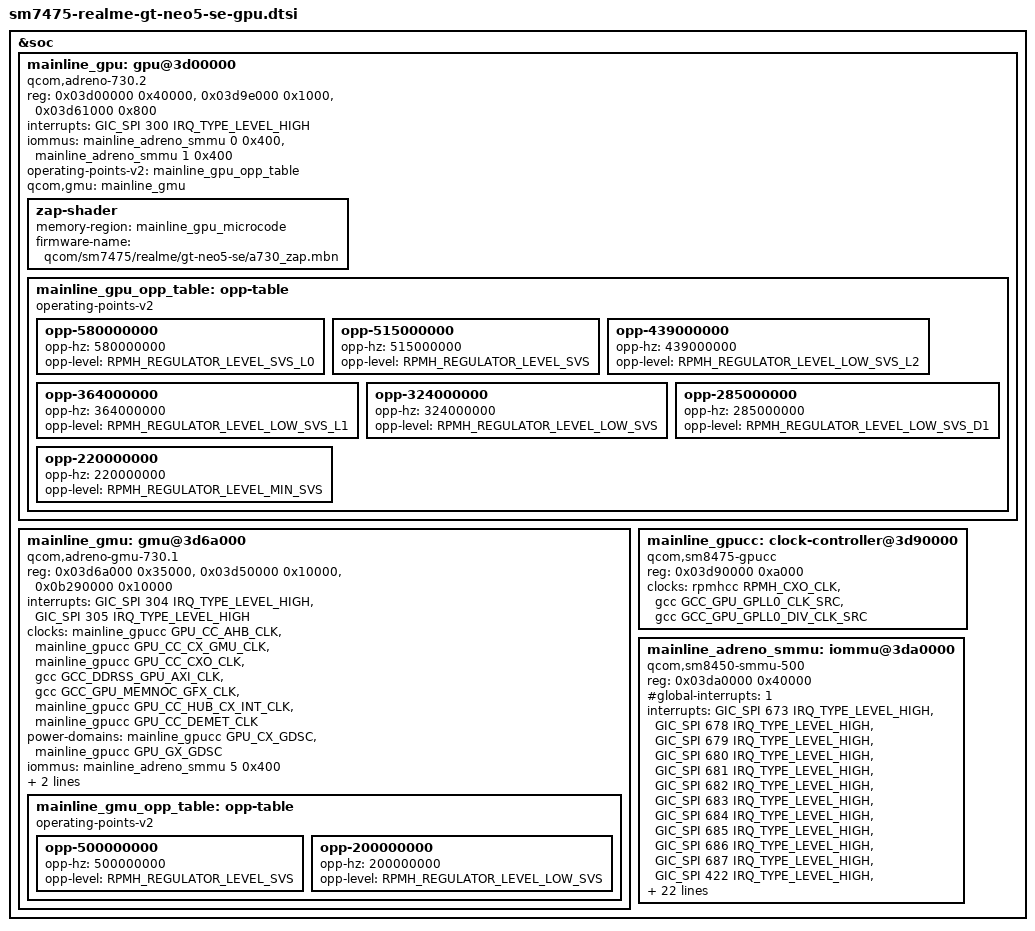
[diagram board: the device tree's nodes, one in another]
// SPDX-License-Identifier: (GPL-2.0-only OR BSD-3-Clause)
/* Cape GPU: stock chip ID 0x07030002, 2 MiB GMEM, 220..580 MHz. */
#include <dt-bindings/clock/qcom,sm8450-gpucc.h>

&soc {
	mainline_gpu: gpu@3d00000 {
		compatible = "qcom,adreno-730.2", "qcom,adreno";
		reg = <0x03d00000 0x40000>,
		      <0x03d9e000 0x1000>,
		      <0x03d61000 0x800>;
		reg-names = "kgsl_3d0_reg_memory",
			    "cx_mem",
			    "cx_dbgc";

		interrupts = <GIC_SPI 300 IRQ_TYPE_LEVEL_HIGH>;

		iommus = <&mainline_adreno_smmu 0 0x400>,
			 <&mainline_adreno_smmu 1 0x400>;

		operating-points-v2 = <&mainline_gpu_opp_table>;

		qcom,gmu = <&mainline_gmu>;
		#cooling-cells = <2>;

		status = "okay";

		zap-shader {
			memory-region = <&mainline_gpu_microcode>;
			firmware-name = "qcom/sm7475/realme/gt-neo5-se/a730_zap.mbn";
		};

		mainline_gpu_opp_table: opp-table {
			compatible = "operating-points-v2";

			opp-580000000 {
				opp-hz = /bits/ 64 <580000000>;
				opp-level = <RPMH_REGULATOR_LEVEL_SVS_L0>;
			};

			opp-515000000 {
				opp-hz = /bits/ 64 <515000000>;
				opp-level = <RPMH_REGULATOR_LEVEL_SVS>;
			};

			opp-439000000 {
				opp-hz = /bits/ 64 <439000000>;
				opp-level = <RPMH_REGULATOR_LEVEL_LOW_SVS_L2>;
			};

			opp-364000000 {
				opp-hz = /bits/ 64 <364000000>;
				opp-level = <RPMH_REGULATOR_LEVEL_LOW_SVS_L1>;
			};

			opp-324000000 {
				opp-hz = /bits/ 64 <324000000>;
				opp-level = <RPMH_REGULATOR_LEVEL_LOW_SVS>;
			};

			opp-285000000 {
				opp-hz = /bits/ 64 <285000000>;
				opp-level = <RPMH_REGULATOR_LEVEL_LOW_SVS_D1>;
			};

			opp-220000000 {
				opp-hz = /bits/ 64 <220000000>;
				opp-level = <RPMH_REGULATOR_LEVEL_MIN_SVS>;
			};
		};
	};

	mainline_gmu: gmu@3d6a000 {
		compatible = "qcom,adreno-gmu-730.1", "qcom,adreno-gmu";
		reg = <0x03d6a000 0x35000>,
		      <0x03d50000 0x10000>,
		      <0x0b290000 0x10000>;
		reg-names = "gmu", "rscc", "gmu_pdc";

		interrupts = <GIC_SPI 304 IRQ_TYPE_LEVEL_HIGH>,
			     <GIC_SPI 305 IRQ_TYPE_LEVEL_HIGH>;
		interrupt-names = "hfi", "gmu";

		clocks = <&mainline_gpucc GPU_CC_AHB_CLK>,
			 <&mainline_gpucc GPU_CC_CX_GMU_CLK>,
			 <&mainline_gpucc GPU_CC_CXO_CLK>,
			 <&gcc GCC_DDRSS_GPU_AXI_CLK>,
			 <&gcc GCC_GPU_MEMNOC_GFX_CLK>,
			 <&mainline_gpucc GPU_CC_HUB_CX_INT_CLK>,
			 <&mainline_gpucc GPU_CC_DEMET_CLK>;
		clock-names = "ahb",
			      "gmu",
			      "cxo",
			      "axi",
			      "memnoc",
			      "hub",
			      "demet";

		power-domains = <&mainline_gpucc GPU_CX_GDSC>,
				<&mainline_gpucc GPU_GX_GDSC>;
		power-domain-names = "cx",
				     "gx";

		iommus = <&mainline_adreno_smmu 5 0x400>;

		qcom,qmp = <&aoss_qmp>;

		operating-points-v2 = <&mainline_gmu_opp_table>;

		mainline_gmu_opp_table: opp-table {
			compatible = "operating-points-v2";

			opp-500000000 {
				opp-hz = /bits/ 64 <500000000>;
				opp-level = <RPMH_REGULATOR_LEVEL_SVS>;
			};

			opp-200000000 {
				opp-hz = /bits/ 64 <200000000>;
				opp-level = <RPMH_REGULATOR_LEVEL_LOW_SVS>;
			};
		};
	};

	mainline_gpucc: clock-controller@3d90000 {
		compatible = "qcom,sm8475-gpucc";
		reg = <0x03d90000 0xa000>;
		clocks = <&rpmhcc RPMH_CXO_CLK>,
			 <&gcc GCC_GPU_GPLL0_CLK_SRC>,
			 <&gcc GCC_GPU_GPLL0_DIV_CLK_SRC>;
		#clock-cells = <1>;
		#reset-cells = <1>;
		#power-domain-cells = <1>;
	};

	mainline_adreno_smmu: iommu@3da0000 {
		compatible = "qcom,sm8450-smmu-500", "qcom,adreno-smmu",
			     "qcom,smmu-500", "arm,mmu-500";
		reg = <0x03da0000 0x40000>;
		#iommu-cells = <2>;
		#global-interrupts = <1>;
		interrupts = <GIC_SPI 673 IRQ_TYPE_LEVEL_HIGH>,
			     <GIC_SPI 678 IRQ_TYPE_LEVEL_HIGH>,
			     <GIC_SPI 679 IRQ_TYPE_LEVEL_HIGH>,
			     <GIC_SPI 680 IRQ_TYPE_LEVEL_HIGH>,
			     <GIC_SPI 681 IRQ_TYPE_LEVEL_HIGH>,
			     <GIC_SPI 682 IRQ_TYPE_LEVEL_HIGH>,
			     <GIC_SPI 683 IRQ_TYPE_LEVEL_HIGH>,
			     <GIC_SPI 684 IRQ_TYPE_LEVEL_HIGH>,
			     <GIC_SPI 685 IRQ_TYPE_LEVEL_HIGH>,
			     <GIC_SPI 686 IRQ_TYPE_LEVEL_HIGH>,
			     <GIC_SPI 687 IRQ_TYPE_LEVEL_HIGH>,
			     <GIC_SPI 422 IRQ_TYPE_LEVEL_HIGH>,
			     <GIC_SPI 476 IRQ_TYPE_LEVEL_HIGH>,
			     <GIC_SPI 574 IRQ_TYPE_LEVEL_HIGH>,
			     <GIC_SPI 575 IRQ_TYPE_LEVEL_HIGH>,
			     <GIC_SPI 576 IRQ_TYPE_LEVEL_HIGH>,
			     <GIC_SPI 577 IRQ_TYPE_LEVEL_HIGH>,
			     <GIC_SPI 659 IRQ_TYPE_LEVEL_HIGH>,
			     <GIC_SPI 661 IRQ_TYPE_LEVEL_HIGH>,
			     <GIC_SPI 664 IRQ_TYPE_LEVEL_HIGH>,
			     <GIC_SPI 665 IRQ_TYPE_LEVEL_HIGH>,
			     <GIC_SPI 666 IRQ_TYPE_LEVEL_HIGH>,
			     <GIC_SPI 668 IRQ_TYPE_LEVEL_HIGH>,
			     <GIC_SPI 669 IRQ_TYPE_LEVEL_HIGH>,
			     <GIC_SPI 699 IRQ_TYPE_LEVEL_HIGH>,
			     <GIC_SPI 700 IRQ_TYPE_LEVEL_HIGH>;
		clocks = <&mainline_gpucc GPU_CC_CX_GMU_CLK>,
			 <&mainline_gpucc GPU_CC_HUB_CX_INT_CLK>,
			 <&mainline_gpucc GPU_CC_HLOS1_VOTE_GPU_SMMU_CLK>,
			 <&gcc GCC_GPU_MEMNOC_GFX_CLK>,
			 <&gcc GCC_GPU_SNOC_DVM_GFX_CLK>,
			 <&mainline_gpucc GPU_CC_AHB_CLK>;
		clock-names = "gmu",
			      "hub",
			      "hlos",
			      "bus",
			      "iface",
			      "ahb";
		power-domains = <&mainline_gpucc GPU_CX_GDSC>;
		dma-coherent;
	};

};
